# regs register map
Registers from a debugger description file.
Registers are 32-bit, access not given, no defined reset value unless marked. A register's access mark holds for its fields unless they carry their own. Addresses are absolute; registers are grouped by the start of their names; lines under a group give offsets from that group; [hi:lo] are bit positions; {n}, {i} and the like mark numbered series; 'fields as' and 'values as' point back to an identical list; <NAME> marks a mode.

## INT
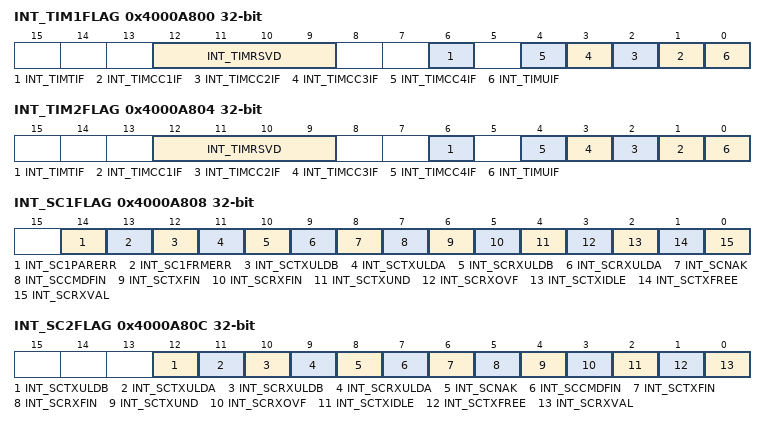
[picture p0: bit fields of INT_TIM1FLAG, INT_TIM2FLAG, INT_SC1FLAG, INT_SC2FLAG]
0x4000A800 INT_TIM1FLAG
  [12:9] INT_TIMRSVD, [6] INT_TIMTIF, [n] INT_TIMCC{n}IF (n=1..4), [0] INT_TIMUIF
0x4000A804 INT_TIM2FLAG
  fields as INT_TIM1FLAG
0x4000A808 INT_SC1FLAG
  [14] INT_SC1PARERR, [13] INT_SC1FRMERR, [12] INT_SCTXULDB, [11] INT_SCTXULDA, [10] INT_SCRXULDB, [9] INT_SCRXULDA, [8] INT_SCNAK, [7] INT_SCCMDFIN, [6] INT_SCTXFIN, [5] INT_SCRXFIN, [4] INT_SCTXUND, [3] INT_SCRXOVF, [2] INT_SCTXIDLE, [1] INT_SCTXFREE, [0] INT_SCRXVAL
0x4000A80C INT_SC2FLAG
  [12] INT_SCTXULDB, [11] INT_SCTXULDA, [10] INT_SCRXULDB, [9] INT_SCRXULDA, [8] INT_SCNAK, [7] INT_SCCMDFIN, [6] INT_SCTXFIN, [5] INT_SCRXFIN, [4] INT_SCTXUND, [3] INT_SCRXOVF, [2] INT_SCTXIDLE, [1] INT_SCTXFREE, [0] INT_SCRXVAL
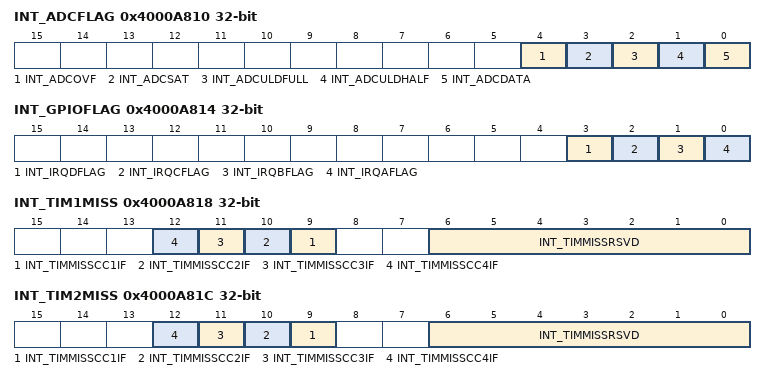
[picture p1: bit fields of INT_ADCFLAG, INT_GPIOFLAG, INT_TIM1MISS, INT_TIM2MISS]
0x4000A810 INT_ADCFLAG
  [4] INT_ADCOVF, [3] INT_ADCSAT, [2] INT_ADCULDFULL, [1] INT_ADCULDHALF, [0] INT_ADCDATA
0x4000A814 INT_GPIOFLAG
  [3] INT_IRQDFLAG, [2] INT_IRQCFLAG, [1] INT_IRQBFLAG, [0] INT_IRQAFLAG
0x4000A818 INT_TIM1MISS
  [n+8] INT_TIMMISSCC{n}IF (n=1..4), [6:0] INT_TIMMISSRSVD
0x4000A81C INT_TIM2MISS
  [n+8] INT_TIMMISSCC{n}IF (n=1..4), [6:0] INT_TIMMISSRSVD
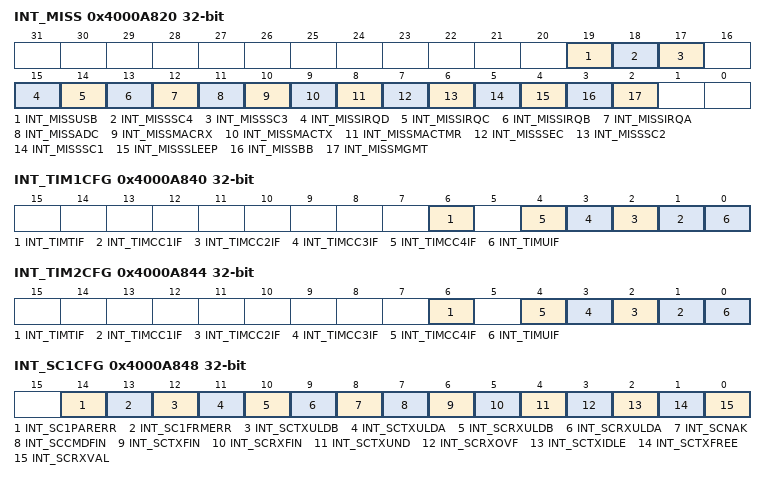
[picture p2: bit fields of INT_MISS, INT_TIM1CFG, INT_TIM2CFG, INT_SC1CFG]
0x4000A820 INT_MISS
  [19] INT_MISSUSB, [18] INT_MISSSC4, [17] INT_MISSSC3, [15] INT_MISSIRQD, [14] INT_MISSIRQC, [13] INT_MISSIRQB, [12] INT_MISSIRQA, [11] INT_MISSADC, [10] INT_MISSMACRX, [9] INT_MISSMACTX, [8] INT_MISSMACTMR, [7] INT_MISSSEC, [6] INT_MISSSC2, [5] INT_MISSSC1, [4] INT_MISSSLEEP, [3] INT_MISSBB, [2] INT_MISSMGMT
0x4000A840 INT_TIM1CFG
  [6] INT_TIMTIF, [n] INT_TIMCC{n}IF (n=1..4), [0] INT_TIMUIF
0x4000A844 INT_TIM2CFG
  [6] INT_TIMTIF, [n] INT_TIMCC{n}IF (n=1..4), [0] INT_TIMUIF
0x4000A848 INT_SC1CFG
  fields as INT_SC1FLAG
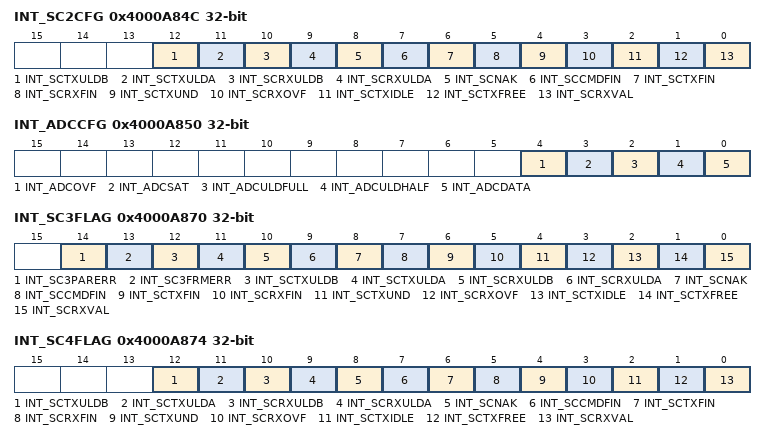
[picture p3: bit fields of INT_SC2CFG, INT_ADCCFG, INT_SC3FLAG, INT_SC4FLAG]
0x4000A84C INT_SC2CFG
  fields as INT_SC2FLAG
0x4000A850 INT_ADCCFG
  fields as INT_ADCFLAG
0x4000A870 INT_SC3FLAG
  [14] INT_SC3PARERR, [13] INT_SC3FRMERR, [12] INT_SCTXULDB, [11] INT_SCTXULDA, [10] INT_SCRXULDB, [9] INT_SCRXULDA, [8] INT_SCNAK, [7] INT_SCCMDFIN, [6] INT_SCTXFIN, [5] INT_SCRXFIN, [4] INT_SCTXUND, [3] INT_SCRXOVF, [2] INT_SCTXIDLE, [1] INT_SCTXFREE, [0] INT_SCRXVAL
0x4000A874 INT_SC4FLAG
  fields as INT_SC2FLAG
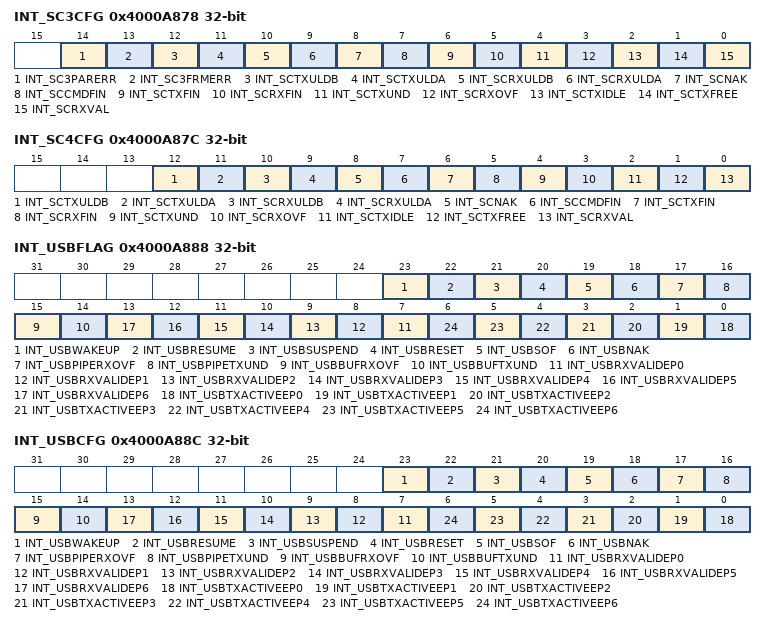
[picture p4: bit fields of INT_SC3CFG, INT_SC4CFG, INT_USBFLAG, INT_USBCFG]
0x4000A878 INT_SC3CFG
  fields as INT_SC3FLAG
0x4000A87C INT_SC4CFG
  fields as INT_SC2FLAG
0x4000A888 INT_USBFLAG
  [23] INT_USBWAKEUP, [22] INT_USBRESUME, [21] INT_USBSUSPEND, [20] INT_USBRESET, [19] INT_USBSOF, [18] INT_USBNAK, [17] INT_USBPIPERXOVF, [16] INT_USBPIPETXUND, [15] INT_USBBUFRXOVF, [14] INT_USBBUFTXUND, [n+7] INT_USBRXVALIDEP{n} (n=0..6), [n] INT_USBTXACTIVEEP{n} (n=0..6)
0x4000A88C INT_USBCFG
  fields as INT_USBFLAG
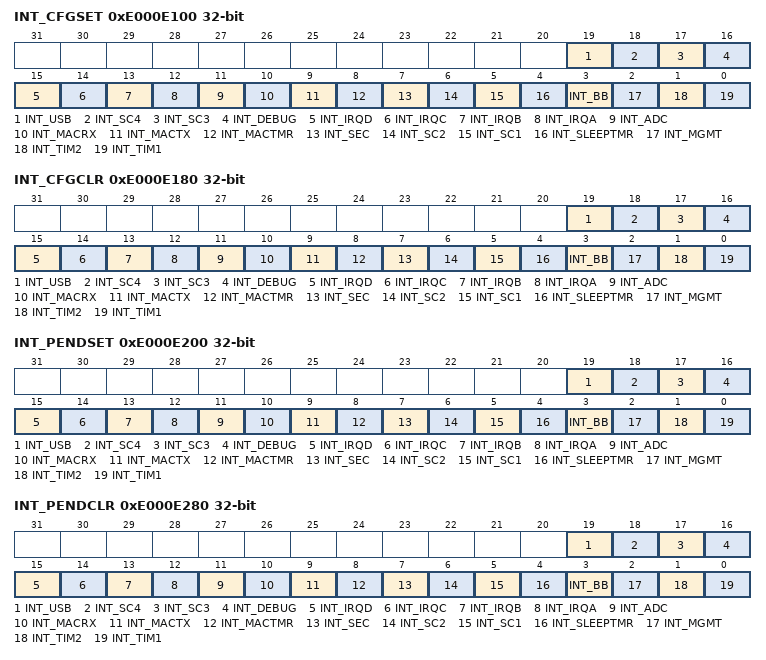
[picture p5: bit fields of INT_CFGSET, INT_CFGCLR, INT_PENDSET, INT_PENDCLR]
0xE000E100 INT_CFGSET
  [19] INT_USB, [18] INT_SC4, [17] INT_SC3, [16] INT_DEBUG, [15] INT_IRQD, [14] INT_IRQC, [13] INT_IRQB, [12] INT_IRQA, [11] INT_ADC, [10] INT_MACRX, [9] INT_MACTX, [8] INT_MACTMR, [7] INT_SEC, [6] INT_SC2, [5] INT_SC1, [4] INT_SLEEPTMR, [3] INT_BB, [2] INT_MGMT, [1] INT_TIM2, [0] INT_TIM1
0xE000E180 INT_CFGCLR
  fields as INT_CFGSET
0xE000E200 INT_PENDSET
  fields as INT_CFGSET
0xE000E280 INT_PENDCLR
  fields as INT_CFGSET
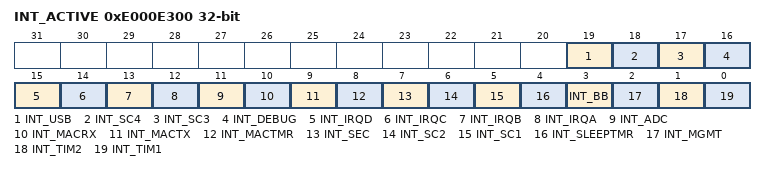
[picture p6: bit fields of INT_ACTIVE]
0xE000E300 INT_ACTIVE
  fields as INT_CFGSET

## SC1
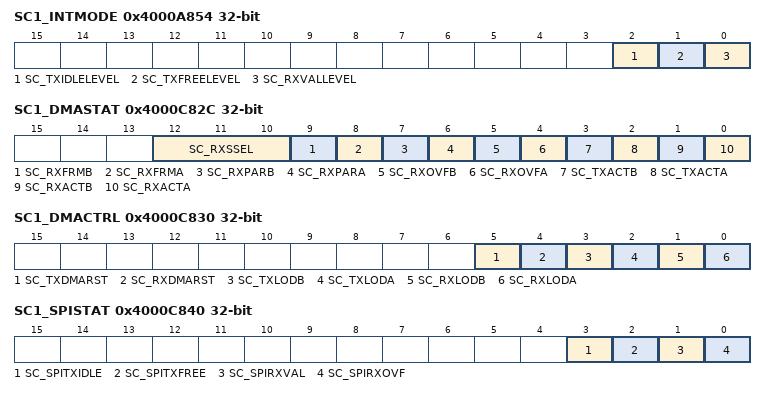
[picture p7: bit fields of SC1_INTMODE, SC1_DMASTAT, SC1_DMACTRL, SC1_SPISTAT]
0x4000A854 SC1_INTMODE
  [2] SC_TXIDLELEVEL, [1] SC_TXFREELEVEL, [0] SC_RXVALLEVEL
0x4000C800 SC1_RXBEGA
0x4000C804 SC1_RXENDA
0x4000C808 SC1_RXBEGB
0x4000C80C SC1_RXENDB
0x4000C810 SC1_TXBEGA
0x4000C814 SC1_TXENDA
0x4000C818 SC1_TXBEGB
0x4000C81C SC1_TXENDB
0x4000C820 SC1_RXCNTA
0x4000C824 SC1_RXCNTB
0x4000C828 SC1_TXCNT
0x4000C82C SC1_DMASTAT
  [12:10] SC_RXSSEL, [9] SC_RXFRMB, [8] SC_RXFRMA, [7] SC_RXPARB, [6] SC_RXPARA, [5] SC_RXOVFB, [4] SC_RXOVFA, [3] SC_TXACTB, [2] SC_TXACTA, [1] SC_RXACTB, [0] SC_RXACTA
0x4000C830 SC1_DMACTRL
  [5] SC_TXDMARST, [4] SC_RXDMARST, [3] SC_TXLODB, [2] SC_TXLODA, [1] SC_RXLODB, [0] SC_RXLODA
0x4000C834 SC1_RXERRA
0x4000C838 SC1_RXERRB
0x4000C83C SC1_DATA
0x4000C840 SC1_SPISTAT
  [3] SC_SPITXIDLE, [2] SC_SPITXFREE, [1] SC_SPIRXVAL, [0] SC_SPIRXOVF
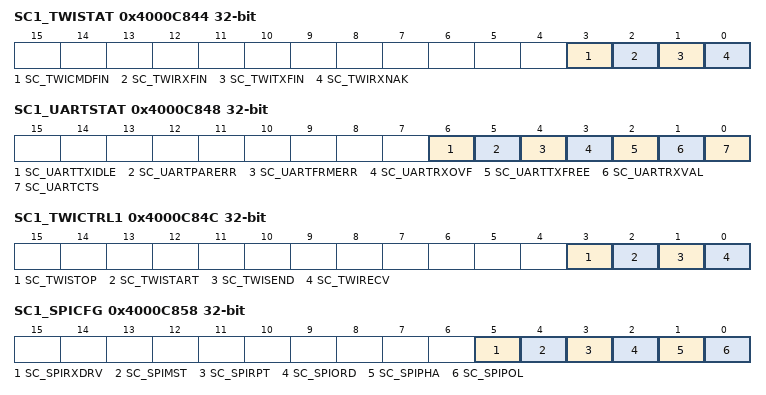
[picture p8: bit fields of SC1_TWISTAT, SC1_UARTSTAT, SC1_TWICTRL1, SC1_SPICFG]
0x4000C844 SC1_TWISTAT
  [3] SC_TWICMDFIN, [2] SC_TWIRXFIN, [1] SC_TWITXFIN, [0] SC_TWIRXNAK
0x4000C848 SC1_UARTSTAT
  [6] SC_UARTTXIDLE, [5] SC_UARTPARERR, [4] SC_UARTFRMERR, [3] SC_UARTRXOVF, [2] SC_UARTTXFREE, [1] SC_UARTRXVAL, [0] SC_UARTCTS
0x4000C84C SC1_TWICTRL1
  [3] SC_TWISTOP, [2] SC_TWISTART, [1] SC_TWISEND, [0] SC_TWIRECV
0x4000C850 SC1_TWICTRL2
0x4000C854 SC1_MODE
0x4000C858 SC1_SPICFG
  [5] SC_SPIRXDRV, [4] SC_SPIMST, [3] SC_SPIRPT, [2] SC_SPIORD, [1] SC_SPIPHA, [0] SC_SPIPOL
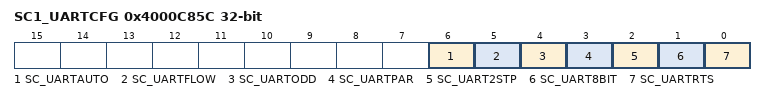
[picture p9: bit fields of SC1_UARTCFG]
0x4000C85C SC1_UARTCFG
  [6] SC_UARTAUTO, [5] SC_UARTFLOW, [4] SC_UARTODD, [3] SC_UARTPAR, [2] SC_UART2STP, [1] SC_UART8BIT, [0] SC_UARTRTS
0x4000C860 SC1_RATELIN
0x4000C864 SC1_RATEEXP
0x4000C868 SC1_UARTPER
0x4000C86C SC1_UARTFRAC
0x4000C870 SC1_RXCNTSAVED

## Notices in the file
Copyright 2014 Silicon Laboratories, Inc.
